# nrf5001 register map
Vendor: Nordic Semiconductor; Series: nRF50; File version: 1
CPU: CM0 r0p4, little endian, no MPU, no FPU, 2 interrupt priority bits, 32 interrupts
Registers are 32-bit, read-write, reset 0x0 unless marked. A register's access mark holds for its fields unless they carry their own. Offsets are from the block's base; [hi:lo] are bit positions; lines under a group give offsets from that group; {n}, {i} and the like mark numbered series; 'fields as' and 'values as' point back to an identical list.

## UICR — User Information Configuration Registers
Base 0x10001000
0x00 APPROTECT — Access port protection
  [31:0] PALL — Blocks debugger read/write access to all CPU registers and memory mapped addresses except for the control access port registers. Between reset and automatic readout, the system is protected Using any value except Unprotected will lead to the protection being enabled.
    0xFFFFFFFF=Unprotected; 0=Protected
0x24 TINSTANCE reset 0xFFFFFFFF — SW-DP Target instance
  [31:28] TINSTANCE — TINSTANCE bits are negated and used in the SW-DP DLPIDR.TINSTANCE field. E.g. 0xF in this field is translated to 0x0 in DLPIDR.TINSTANCE field.
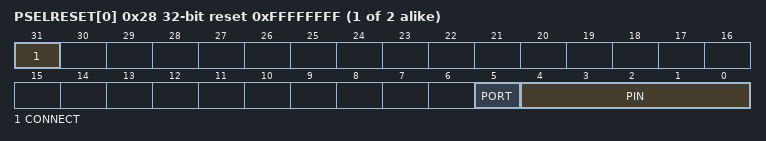
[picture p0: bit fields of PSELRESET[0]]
{0x28+4i} PSELRESET[{i}] (i=0..1) reset 0xFFFFFFFF — Description collection: Mapping of the nRESET function (see POWER chapter for details)
  [31] CONNECT — Connection
    1=Disconnected; 0=Connected
  [5] PORT — Port number onto which nRESET is exposed
  [4:0] PIN — GPIO pin number onto which nRESET is exposed

## PAMLI — Peripheral AHB Multi-Layer Interface
Base 0x40020000
0xE00 RAMPRI group — RAM configurable priority configuration structure
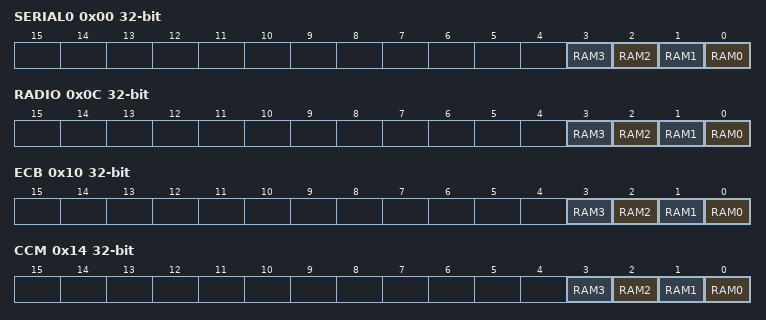
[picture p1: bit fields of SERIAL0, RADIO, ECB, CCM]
  0x00 SERIAL0 — AHB bus master priority register for SPIM0, SPIS0, TWIM0, TWIS0 and UARTE0
    [all] fields
      0=Pri0 (Priority 0); 1=Pri1 (Priority 1)
    [n] RAM{n} (n=0..3) — Priority register for RAM AHB slave {n}
  0x0C RADIO — AHB bus master priority register for RADIO
    fields as RAMPRI.SERIAL0
  0x10 ECB — AHB bus master priority register for ECB
    fields as RAMPRI.SERIAL0
  0x14 CCM — AHB bus master priority register for CCM
    fields as RAMPRI.SERIAL0
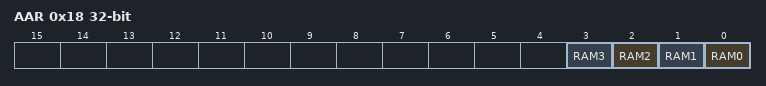
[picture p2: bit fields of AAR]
  0x18 AAR — AHB bus master priority register for AAR
    fields as RAMPRI.SERIAL0

## VMC — Volatile Memory controller
Base 0x40022000
{0x600+0x10*i} RAM[{i}] (i=0..1) group — Unspecified
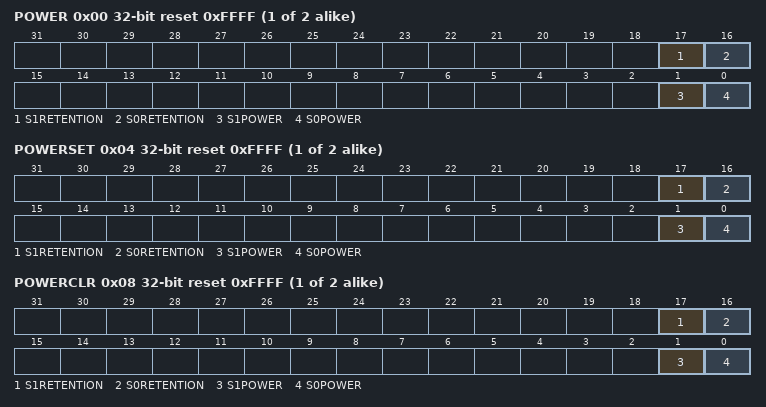
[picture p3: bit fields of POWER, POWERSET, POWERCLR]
  0x00 POWER reset 0xFFFF — Description cluster: RAM[n] power control register
    [all] fields
      0=Off; 1=On
    [17] S1RETENTION — Keep retention on RAM section S1 of RAM[n] when RAM section is switched off
    [16] S0RETENTION — Keep retention on RAM section S0 of RAM[n] when RAM section is switched off
    [1] S1POWER — Keep RAM section S1 of RAM[n] on or off in System ON mode
    [0] S0POWER — Keep RAM section S0 of RAM[n] on or off in System ON mode
  0x04 POWERSET reset 0xFFFF — Description cluster: RAM[n] power control set register
    [all] fields
      1=On
    [17] S1RETENTION — Keep retention on RAM section S1 of RAM[n] when RAM section is switched off
    [16] S0RETENTION — Keep retention on RAM section S0 of RAM[n] when RAM section is switched off
    [1] S1POWER — Keep RAM section S1 of RAM[n] on or off in System ON mode
    [0] S0POWER — Keep RAM section S0 of RAM[n] on or off in System ON mode
  0x08 POWERCLR reset 0xFFFF — Description cluster: RAM[n] power control clear register
    [all] fields
      1=Off
    [17] S1RETENTION — Keep retention on RAM section S1 of RAM[n] when RAM section is switched off
    [16] S0RETENTION — Keep retention on RAM section S0 of RAM[n] when RAM section is switched off
    [1] S1POWER — Keep RAM section S1 of RAM[n] on or off in System ON mode
    [0] S0POWER — Keep RAM section S0 of RAM[n] on or off in System ON mode

## BPROT — Block Protect
Base 0x40023000
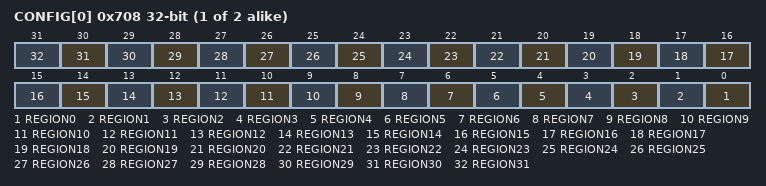
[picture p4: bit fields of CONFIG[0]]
{0x708+4i} CONFIG[{i}] (i=0..1) — Description collection: Block protect configuration register n.
  [all] fields
    0=Disabled (Disable protection.); 1=Enabled (Enable protection.)
  [n] REGION{n} (n=0..31) — Enable protection for region {n}. Writing '0' has no effect.

## RAMBIST0 — The RamBist perform hardware accelerated RAM tests 0
Base 0x40025000
Same registers: RAMBIST1 0x40026000
0x400 STATUS group — Unspecified
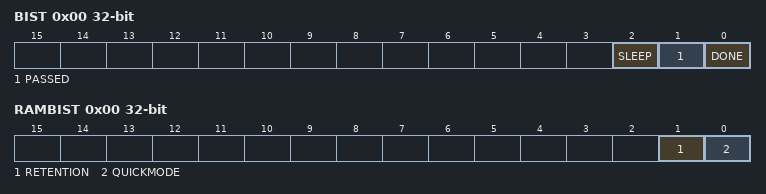
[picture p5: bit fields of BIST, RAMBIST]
  0x00 BIST ro — Status of the BIST
    [2] SLEEP — The RamBist is currently waiting for a RUNBIST handshake, see retention test protocol
    [1] PASSED — The RamBist passed, meaning all the compares in the pattern succeded
    [0] DONE — The RamBist is finished
  0x04 FAULTY ro — Which blocks are failing the test
    [15:0] BLOCKS — 0 if block has no miscompares, 1 if block has miscompares. Size and indices are equal to CLAMP.BLOCKS
0x500 RUN — Run the BIST engine, must be kept 1 until the BIST is finished
  [0] BIST — When 1, the RamBist runs
0x504 CONFIG group — Unspecified
  0x00 RAMBIST — Configuration of the RamBist itself. When none of the fields are set, it runs the standard production test BIST.
    [1] RETENTION — Runs the retention test protocol, does only exists if the connected RAMs require retention test
    [0] QUICKMODE — Runs a fast subset of the tests, intended for debug only
  0x04 RAM — Override of the RAM configuration
    [6:0] CONFIG — Depending on the RAM Vendor, this field is different. The reset value is also vendor dependent. (Noted as Vendor[width]: [Signal[width]=..].) TSMC0[4:0]: WTSEL[2:0], RTSEL[1:0]. TSMC1[1:0]: TSEL[1:0]. MobileSemi[6:0]: BTRIM[3:0], WM, RM, RWM.
  0x08 CLAMP — Clamp/Exclude certain blocks from the test
    [15:0] BLOCKS — Bit indexed, if an entry is 1, the block is not receiving stimuli, and excluded from the comparison. Parameterized with the number of RAM macros

## Notices in the file
Copyright (c) 2010 - 2020, Nordic Semiconductor ASA
All rights reserved.
Redistribution and use in source and binary forms, with or without modification,
are permitted provided that the following conditions are met:
1. Redistributions of source code must retain the above copyright notice, this
list of conditions and the following disclaimer.
2. Redistributions in binary form, except as embedded into a Nordic
Semiconductor ASA integrated circuit in a product or a software update for
such product, must reproduce the above copyright notice, this list of
conditions and the following disclaimer in the documentation and/or other
materials provided with the distribution.
3. Neither the name of Nordic Semiconductor ASA nor the names of its
contributors may be used to endorse or promote products derived from this
software without specific prior written permission.
4. This software, with or without modification, must only be used with a
Nordic Semiconductor ASA integrated circuit.
5. Any software provided in binary form under this license must not be reverse
engineered, decompiled, modified and/or disassembled.
THIS SOFTWARE IS PROVIDED BY NORDIC SEMICONDUCTOR ASA "AS IS" AND ANY EXPRESS
OR IMPLIED WARRANTIES, INCLUDING, BUT NOT LIMITED TO, THE IMPLIED WARRANTIES
OF MERCHANTABILITY, NONINFRINGEMENT, AND FITNESS FOR A PARTICULAR PURPOSE ARE
DISCLAIMED. IN NO EVENT SHALL NORDIC SEMICONDUCTOR ASA OR CONTRIBUTORS BE
LIABLE FOR ANY DIRECT, INDIRECT, INCIDENTAL, SPECIAL, EXEMPLARY, OR
CONSEQUENTIAL DAMAGES (INCLUDING, BUT NOT LIMITED TO, PROCUREMENT OF SUBSTITUTE
GOODS OR SERVICES; LOSS OF USE, DATA, OR PROFITS; OR BUSINESS INTERRUPTION)
HOWEVER CAUSED AND ON ANY THEORY OF LIABILITY, WHETHER IN CONTRACT, STRICT
LIABILITY, OR TORT (INCLUDING NEGLIGENCE OR OTHERWISE) ARISING IN ANY WAY OUT
OF THE USE OF THIS SOFTWARE, EVEN IF ADVISED OF THE POSSIBILITY OF SUCH DAMAGE.
